VERSION ""

NS_ :

BS_:

BU_: DBG DRIVER MOTOR SENSOR

BO_ 100 DRIVER_HEARTBEAT: 1 DRIVER
 SG_ DRIVER_HEARTBEAT_CMD : 0|8@1+ (1,0) [0|0] "" SENSOR,MOTOR

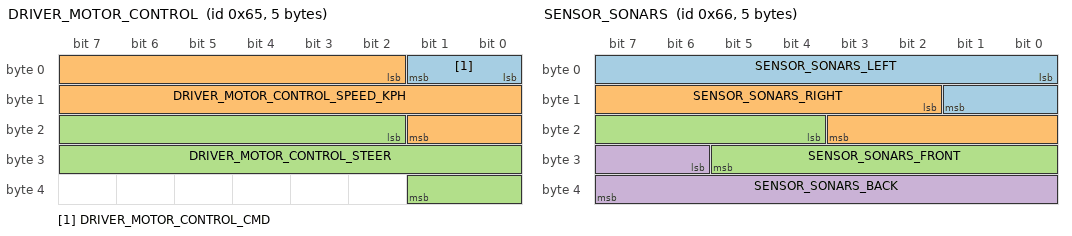
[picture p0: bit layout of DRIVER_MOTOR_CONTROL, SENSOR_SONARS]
BO_ 101 DRIVER_MOTOR_CONTROL: 5 DRIVER
 SG_ DRIVER_MOTOR_CONTROL_CMD : 0|2@1+ (1,0) [0|5] "" MOTOR
 SG_ DRIVER_MOTOR_CONTROL_SPEED_KPH : 2|16@1+ (0.1, 0) [0.0|30.0] "kph" MOTOR
 SG_ DRIVER_MOTOR_CONTROL_STEER : 18|16@1+ (1,0) [-2|2] "degrees" MOTOR

BO_ 102 SENSOR_SONARS: 5 SENSOR
 SG_ SENSOR_SONARS_LEFT : 0|10@1+ (1,0) [0|800] "inch" DRIVER
 SG_ SENSOR_SONARS_RIGHT : 10|10@1+ (1,0) [0|0] "inch" DRIVER
 SG_ SENSOR_SONARS_FRONT : 20|10@1+ (1,0) [0|0] "inch" DRIVER
 SG_ SENSOR_SONARS_BACK : 30|10@1+ (1,0) [0|0] "inch" DRIVER

CM_ BU_ DRIVER "The driver controller driving the car";
CM_ BU_ MOTOR "The motor controller of the car";
CM_ BU_ SENSOR "The sensor controller of the car";
CM_ BO_ 100 "Sync message used to synchronize the controllers";
CM_ SG_ 100 DRIVER_HEARTBEAT_CMD "Heartbeat command from the driver";

BA_DEF_ "BusType" STRING ;
BA_DEF_ BO_ "GenMsgCycleTime" INT 0 0;
BA_DEF_ SG_ "FieldType" STRING ;

BA_DEF_DEF_ "BusType" "CAN";
BA_DEF_DEF_ "FieldType" "";
BA_DEF_DEF_ "GenMsgCycleTime" 0;

BA_ "GenMsgCycleTime" BO_ 100 1000;
BA_ "GenMsgCycleTime" BO_ 101 50;
BA_ "GenMsgCycleTime" BO_ 102 50;
BA_ "FieldType" SG_ 100 DRIVER_HEARTBEAT_CMD "DRIVER_HEARTBEAT_CMD";
BA_ "FieldType" SG_ 101 DRIVER_MOTOR_CONTROL_CMD "DRIVER_MOTOR_CONTROL_CMD";

VAL_ 100 DRIVER_HEARTBEAT_CMD 2 "DRIVER_HEARTBEAT_CMD_REBOOT" 1 "DRIVER_HEARTBEAT_CMD_SYNC" 0 "DRIVER_HEARTBEAT_CMD_NOOP" ;
VAL_ 101 DRIVER_MOTOR_CONTROL_CMD 2 "DRIVER_MOTOR_CONTROL_CMD_STOP" 1 "DRIVER_MOTOR_CONTROL_CMD_REVERSE" 0 "DRIVER_MOTOR_CONTROL_CMD_FORWARD" ;
